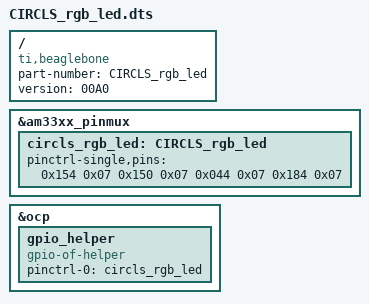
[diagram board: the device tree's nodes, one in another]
/*
* Copyright (C) 2012 Texas Instruments Incorporated - http://www.ti.com/
*
* This program is free software; you can redistribute it and/or modify
* it under the terms of the GNU General Purpose License Version 2 as
* published by the Free Software Foundation
*
* Original from: github.com/jadonk/validation-scripts/blob/master/test-capemgr/
*
* Modified by Derek Molloy for the example on www.derekmolloy.ie
* that maps GPIO pins for the example
*
* Modified again by Fritz Reese for a custom RGB LED circuit.
*
* Uses pins 21-24 on the BBB as pull-down GPIOs.
*
*   PIN GPIO
*   21	GPIO_3
*   22	GPIO_2
*   23	GPIO_49
*   24	GPIO_15
*
*/

/dts-v1/;
/plugin/;

/{
  compatible = "ti,beaglebone", "ti,beaglebone-black";
  part-number = "CIRCLS_rgb_led";
  version = "00A0";

  fragment@0 {
    target = <&am33xx_pinmux>;

    __overlay__ {
      circls_rgb_led: CIRCLS_rgb_led {
        pinctrl-single,pins = <
          0x154 0x07  // P9_21 PINS$85 GPIO0_03 =  3 Output Mode7 pulldown
          0x150 0x07  // P9_22 PINS$84 GPIO0_02 =  2 Output Mode7 pulldown
          0x044 0x07  // P9_23 PINS$17 GPIO1_17 = 49 Output Mode7 pullupdown
          0x184 0x07  // P9_24 PINS$97 GPIO0_15 = 15 Output Mode7 pullupdown
          /* OUTPUT  GPIO(mode7) 0x07 pulldown, 0x17 pullup, 0x?f no pullx */
          /* INPUT   GPIO(mode7) 0x27 pulldown, 0x37 pullup, 0x?f no pullx */
        >;
      };
    };
  };

  fragment@1 {
    target = <&ocp>;
    __overlay__ {
      gpio_helper {
        compatible = "gpio-of-helper";
        status = "okay";
        pinctrl-names = "default";
        pinctrl-0 = <&circls_rgb_led>;
      };
    };
  };
};
